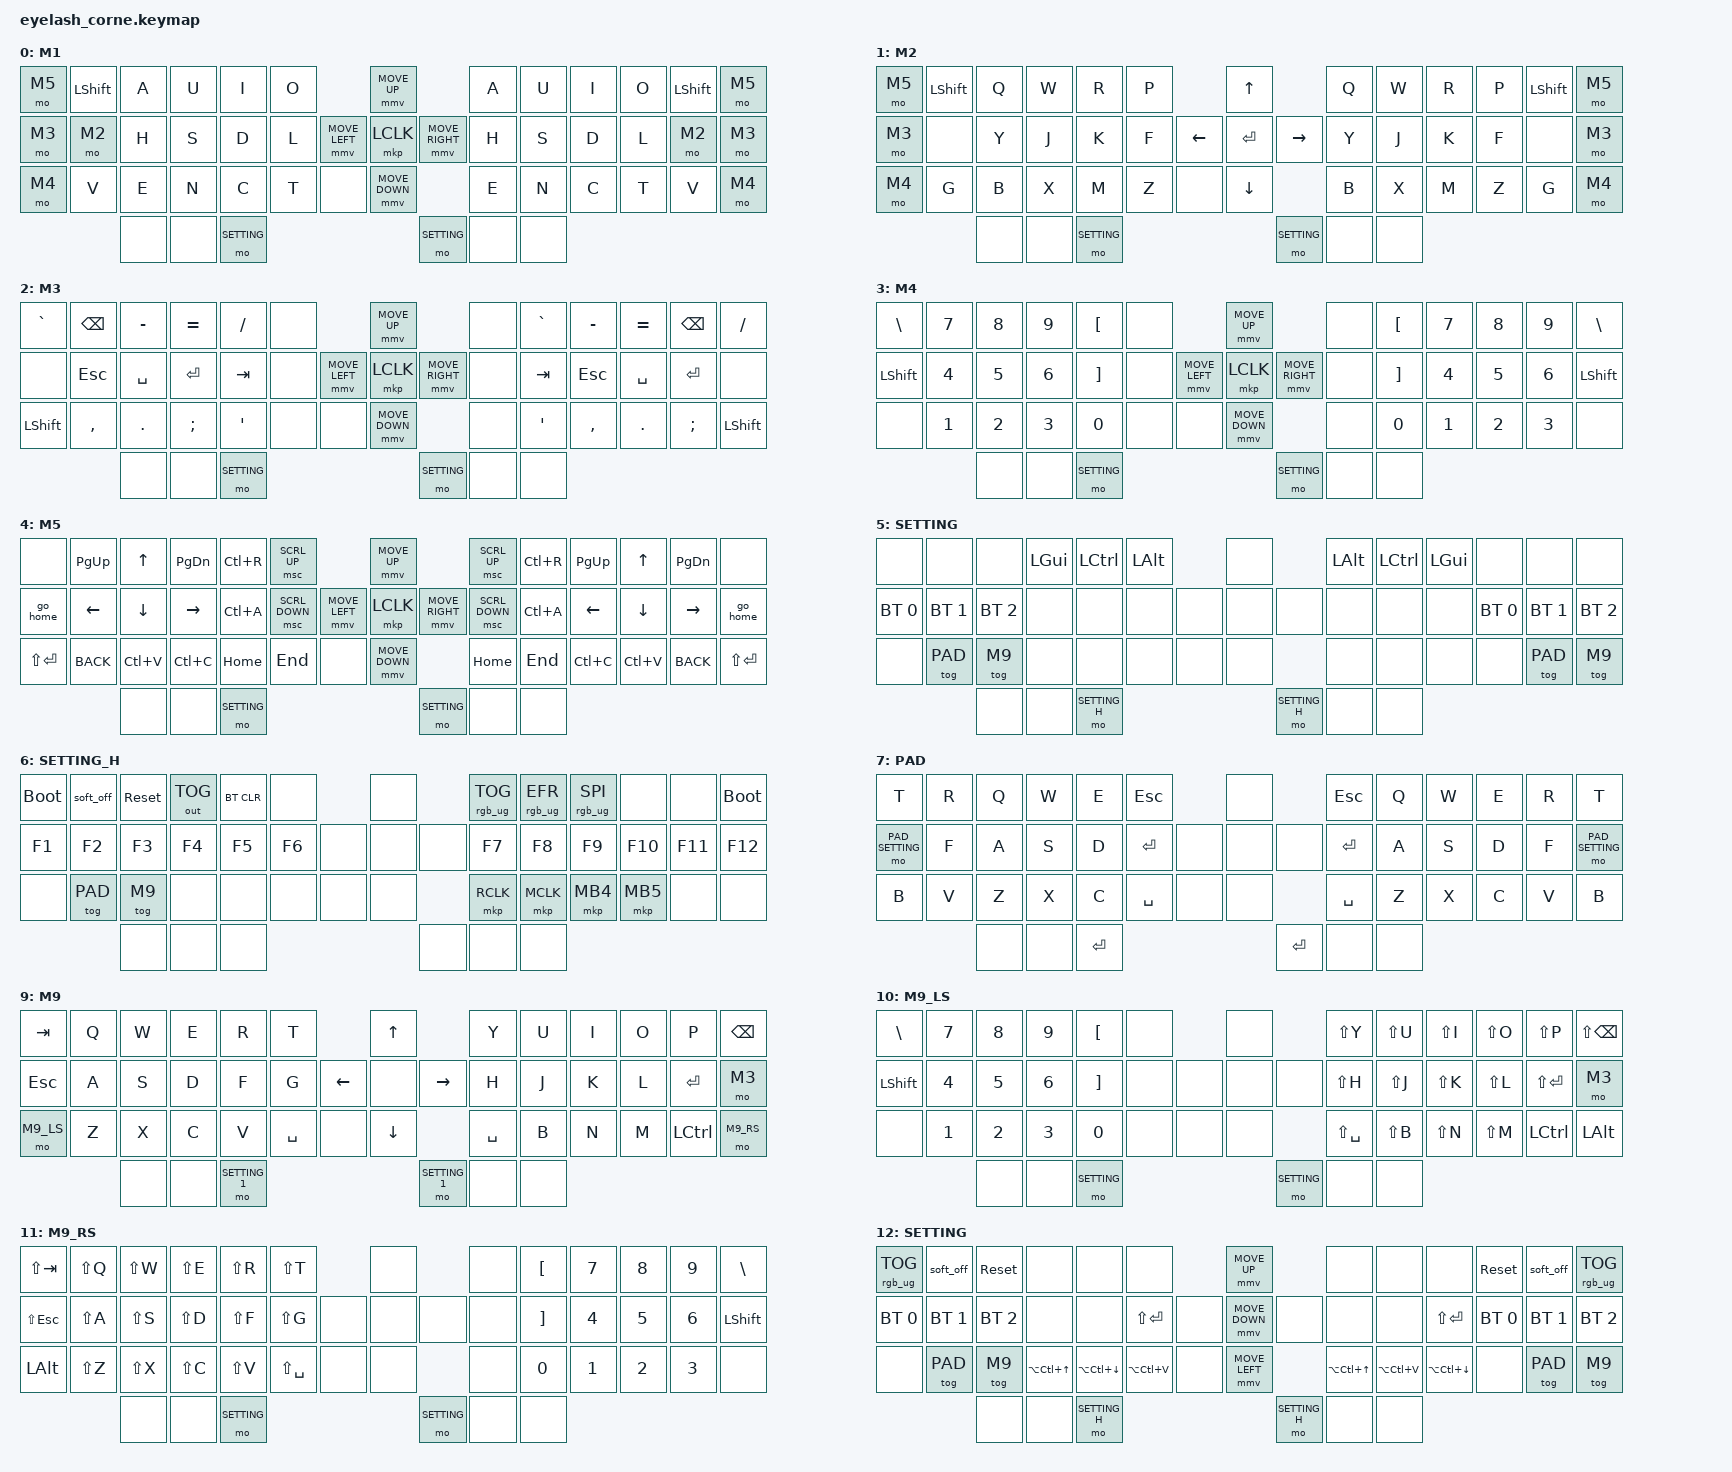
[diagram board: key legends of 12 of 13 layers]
#include <behaviors.dtsi>
#include <dt-bindings/zmk/bt.h>
#include <dt-bindings/zmk/keys.h>
#include <dt-bindings/zmk/mouse.h>
#include <dt-bindings/zmk/outputs.h>
#include <dt-bindings/zmk/rgb.h>

#include <input/processors.dtsi>


/*

   &mmv_input_listener {
       input-processors = <&zip_xy_scaler 2 1>;
   };

   &msc_input_listener {
       input-processors = <&zip_xy_scaler 2 1>;
   };

 */

#define ZMK_MOUSE_DEFAULT_MOVE_VAL 1200  // 600
#define ZMK_MOUSE_DEFAULT_SCRL_VAL 20    // 10
#define M1           0
#define M2           1
#define M3           2
#define M4           3
#define M5           4
#define SETTING      5
#define SETTING_H    6
#define PAD          7
#define PAD_SETTING  8
#define M9           9
#define M9_LS        10
#define M9_RS        11
#define SETTING_1    12

/ {
    macros {
        go_home: go_home {
            compatible = "zmk,behavior-macro";
            #binding-cells = <0>;
            bindings
                = <&macro_press &kp LGUI>
				, <&macro_wait_time 64>
                , <&macro_tap &kp ENTER>
                , <&macro_release &kp LGUI>
                ;
        };
    };

    rgb_encoder: rgb_encoder {
        compatible = "zmk,behavior-sensor-rotate";
        #sensor-binding-cells = <0>;
        bindings = <&rgb_ug RGB_BRI>, <&rgb_ug RGB_BRD>;
    };

    //scroll_encoder: scroll_encoder {
    //    compatible = "zmk,behavior-sensor-rotate";
    //    #sensor-binding-cells = <2>;
    //    bindings = <&msc SCRL_DOWN>, <&msc SCRL_UP>;
    //    tap-ms = <10>;
    //};
	rot_kp: sensor_rotate_kp {
		compatible = "zmk,behavior-sensor-rotate-var";
		#sensor-binding-cells = <2>;
		bindings = <&kp>, <&kp>;
		tap-ms = <10>;
	};

    keymap {
        compatible = "zmk,keymap";

        m1 {
            display-name = "M1";
		    bindings = <
&mo M5  &kp LEFT_SHIFT &kp A &kp U &kp I &kp O             	   &mmv MOVE_UP 			  &kp A &kp U &kp I &kp O &kp LEFT_SHIFT &mo M5
&mo M3  &mo M2         &kp H &kp S &kp D &kp L  &mmv MOVE_LEFT &mkp LCLK &mmv MOVE_RIGHT  &kp H &kp S &kp D &kp L &mo M2 		 &mo M3
&mo M4  &kp V          &kp E &kp N &kp C &kp T  &none          &mmv MOVE_DOWN             &kp E &kp N &kp C &kp T &kp V  		 &mo M4
					   &none  &none  &mo SETTING             		      	  &mo SETTING  &none  &none
            >;
			sensor-bindings = <&rot_kp PAGE_DOWN PAGE_UP>;
			//sensor-bindings = <&scroll_encoder>;
        };

        m2 {
            display-name = "M2";
            bindings = <
&mo M5 &kp LEFT_SHIFT &kp Q &kp W &kp R &kp P           &kp UP       		 &kp Q &kp W &kp R &kp P &kp LEFT_SHIFT &mo M5
&mo M3 &none          &kp Y &kp J &kp K &kp F  &kp LEFT &kp ENTER &kp RIGHT  &kp Y &kp J &kp K &kp F &none 		    &mo M3
&mo M4 &kp G          &kp B &kp X &kp M &kp Z  &none    &kp DOWN             &kp B &kp X &kp M &kp Z &kp G          &mo M4
					  &none  &none  &mo SETTING             						 	 &mo SETTING  &none  &none
            >;
			sensor-bindings = <&rot_kp PAGE_DOWN PAGE_UP>;
        };

        m3 {
            display-name = "M3";
            bindings = <
&kp GRAVE 	   &kp BSPC  &kp MINUS  &kp EQUAL &kp SLASH      &none 				   &mmv MOVE_UP 			  &none &kp GRAVE      &kp MINUS &kp EQUAL  &kp BSPC  &kp SLASH
&none     	   &kp ESC   &kp SPACE  &kp ENTER &kp TAB  	     &none  &mmv MOVE_LEFT &mkp LCLK &mmv MOVE_RIGHT  &none &kp TAB        &kp ESC   &kp SPACE  &kp ENTER &none
&kp LEFT_SHIFT &kp COMMA &kp PERIOD &kp SEMI  &kp APOSTROPHE &none  &none          &mmv MOVE_DOWN             &none &kp APOSTROPHE &kp COMMA &kp PERIOD &kp SEMI  &kp LEFT_SHIFT
								    &none  &none  &mo SETTING     			      					  		  &mo SETTING  &none  &none
            >;
			sensor-bindings = <&rot_kp PAGE_DOWN PAGE_UP>;
        };

        m4 {
            display-name = "M4";
            bindings = <
&kp BACKSLASH  &kp N7  &kp N8  &kp N9  &kp LEFT_BRACKET   &none 				&mmv MOVE_UP 	   	       &none  &kp LEFT_BRACKET   &kp N7  &kp N8  &kp N9  &kp BACKSLASH
&kp LEFT_SHIFT &kp N4  &kp N5  &kp N6  &kp RIGHT_BRACKET  &none  &mmv MOVE_LEFT &mkp LCLK &mmv MOVE_RIGHT  &none  &kp RIGHT_BRACKET  &kp N4  &kp N5  &kp N6  &kp LEFT_SHIFT
&none          &kp N1  &kp N2  &kp N3  &kp N0             &none  &none			&mmv MOVE_DOWN             &none  &kp N0             &kp N1  &kp N2  &kp N3  &none
							   &none  &none  &mo SETTING                      	   						   &mo SETTING  &none  &none
            >;
			sensor-bindings = <&rot_kp PAGE_DOWN PAGE_UP>;
        };

        m5 {
            display-name = "M5";
            bindings = <
&none         &kp PAGE_UP    &kp UP_ARROW   &kp PAGE_DOWN   &kp LC(R)  &msc SCRL_UP   				  &mmv MOVE_UP    		     &msc SCRL_UP        &kp LC(R)  &kp PAGE_UP     &kp UP_ARROW    &kp PAGE_DOWN    &none
&go_home      &kp LEFT_ARROW &kp DOWN_ARROW &kp RIGHT_ARROW &kp LC(A)  &msc SCRL_DOWN  &mmv MOVE_LEFT &mkp LCLK &mmv MOVE_RIGHT  &msc SCRL_DOWN        &kp LC(A)  &kp LEFT_ARROW  &kp DOWN_ARROW  &kp RIGHT_ARROW  &go_home
&kp LS(ENTER) &kp K_BACK     &kp LC(V)      &kp LC(C)		&kp HOME   &kp END         &none 		  &mmv MOVE_DOWN             &kp HOME   &kp END      &kp LC(C)       &kp LC(V)       &kp K_BACK       &kp LS(ENTER)
										  &none  &none  &mo SETTING                                                    		   &mo SETTING  &none  &none
            >;
			sensor-bindings = <&rot_kp PAGE_DOWN PAGE_UP>;
        };

        setting {
            display-name = "SETTING";
            bindings = <
&none 		 &none        &none   	   &kp LGUI &kp LCTRL &kp LALT        &none    	   &kp LALT &kp LCTRL &kp LGUI &none        &none        &none
&bt BT_SEL 0 &bt BT_SEL 1 &bt BT_SEL 2 &none    &none     &none     &none &none &none  &none    &none     &none &bt BT_SEL 0 &bt BT_SEL 1 &bt BT_SEL 2
&none        &tog PAD     &tog M9      &none    &none 	  &none     &none &none    	   &none    &none     &none &none        &tog PAD     &tog M9
										  &none &none  &mo SETTING_H 	   						     &mo SETTING_H &none  &none
            >;
            sensor-bindings = <&inc_dec_kp K_VOLUME_UP K_VOLUME_DOWN>;
        };

        setting_h {
            display-name = "SETTING_H";
            bindings = <
&bootloader &soft_off &sys_reset &out OUT_TOG &bt BT_CLR &none 		  &none        &rgb_ug RGB_TOG &rgb_ug RGB_EFR &rgb_ug RGB_SPI &none &none &bootloader
&kp F1 &kp F2 &kp F3 &kp F4 &kp F5 &kp F6 						&none &none &none  &kp F7 &kp F8 &kp F9 &kp F10 &kp F11 &kp F12
&none &tog PAD &tog M9 &none &none &none  						&none &none    	   &mkp RCLK &mkp MCLK &mkp MB4 &mkp MB5 &none &none
								&none &none  &none              &none &none &none
            >;
            sensor-bindings = <&rgb_encoder>;
        };

        pad {
            display-name = "PAD";
		    bindings = <
&kp T           &kp R &kp Q  &kp W &kp E &kp ESC   		  &none        &kp ESC   &kp Q &kp W  &kp E &kp R &kp T
&mo PAD_SETTING &kp F &kp A  &kp S &kp D &kp ENTER  &none &none &none  &kp ENTER &kp A &kp S  &kp D &kp F &mo PAD_SETTING
&kp B           &kp V &kp Z  &kp X &kp C &kp SPACE  &none &none    	   &kp SPACE &kp Z &kp X  &kp C &kp V &kp B
							   &none  &none  &kp ENTER                       &kp ENTER  &none  &none
            >;
			sensor-bindings = <&rot_kp PAGE_DOWN PAGE_UP>;
        };

        pad_setting {
            display-name = "PAD_SETTING";
		    bindings = <
&none &none &none  &none    &none  &none        &none        &none &none &none     &none &none &none
&none &none &none  &tog PAD &none  &none  &none &none &none  &none &none &tog PAD  &none &none &none
&none &none &none  &none    &none  &none  &none &none        &none &none &none     &none &none &none
					 &none  &none  &none                     	&none  &none  &none
&none
            >;
			sensor-bindings = <&rot_kp PAGE_DOWN PAGE_UP>;
        };

        m9 {
            display-name = "M9";
		    bindings = <
&kp TAB   &kp Q &kp W &kp E &kp R &kp T      			    &kp UP_ARROW       	   &kp Y     &kp U &kp I &kp O &kp P     &kp BSPC
&kp ESC   &kp A &kp S &kp D &kp F &kp G      &kp LEFT_ARROW &none &kp RIGHT_ARROW  &kp H     &kp J &kp K &kp L &kp ENTER &mo M3
&mo M9_LS &kp Z &kp X &kp C &kp V &kp SPACE  &none  		&kp DOWN_ARROW     	   &kp SPACE &kp B &kp N &kp M &kp LCTRL &mo M9_RS       
         			  &none  &none  &mo SETTING_1         						   &mo SETTING_1  &none  &none
            >;
			sensor-bindings = <&rot_kp PAGE_DOWN PAGE_UP>;
        };

        m9_ls {
            display-name = "M9_LS";
		    bindings = <
&kp BACKSLASH &kp N7 &kp N8 &kp N9 &kp LEFT_BRACKET  &none        	   &none        &kp LS(Y)     &kp LS(U) &kp LS(I) &kp LS(O) &kp LS(P)     &kp LS(BSPC)
&kp LSHIFT    &kp N4 &kp N5 &kp N6 &kp RIGHT_BRACKET &none       &none &none &none  &kp LS(H)     &kp LS(J) &kp LS(K) &kp LS(L) &kp LS(ENTER) &mo M3
&none         &kp N1 &kp N2 &kp N3 &kp N0            &none       &none &none        &kp LS(SPACE) &kp LS(B) &kp LS(N) &kp LS(M) &kp LCTRL     &kp LALT
          &none  &none  &mo SETTING   &mo SETTING  &none  &none
            >;
			sensor-bindings = <&rot_kp PAGE_DOWN PAGE_UP>;
        };

        m9_rs {
            display-name = "M9_RS";
		    bindings = <
&kp LS(TAB)  &kp LS(Q)  &kp LS(W)  &kp LS(E)  &kp LS(R)  &kp LS(T)        	  &none        &none  &kp LEFT_BRACKET   &kp N7 &kp N8 &kp N9 &kp BACKSLASH
&kp LS(ESC)  &kp LS(A)  &kp LS(S)  &kp LS(D)  &kp LS(F)  &kp LS(G)      &none &none &none  &none  &kp RIGHT_BRACKET  &kp N4 &kp N5 &kp N6 &kp LSHIFT
&kp LALT     &kp LS(Z)  &kp LS(X)  &kp LS(C)  &kp LS(V)  &kp LS(SPACE)  &none &none 	   &none  &kp N0             &kp N1 &kp N2 &kp N3 &none
         &none  &none  &mo SETTING   &mo SETTING  &none  &none
            >;
			sensor-bindings = <&rot_kp PAGE_DOWN PAGE_UP>;
        };

        setting_1 {
            display-name = "SETTING";
            bindings = <
&rgb_ug RGB_TOG  &soft_off     &sys_reset         &none                 &none                   &none            &mmv MOVE_UP      &none                 &none                   &none 	&sys_reset  &soft_off     &rgb_ug RGB_TOG
&bt BT_SEL 0     &bt BT_SEL 1  &bt BT_SEL 2  &none                 &none                   &kp LS(ENTER)    &none &mmv MOVE_DOWN &none    &none                 &none                   &kp LS(ENTER)    &bt BT_SEL 0     &bt BT_SEL 1  &bt BT_SEL 2
&none           &tog PAD         &tog M9         &kp LA(LC(UP_ARROW))  &kp LA(LC(DOWN_ARROW))  &kp LA(LC(V))   &none  &mmv MOVE_LEFT    &kp LA(LC(UP_ARROW)) &kp LA(LC(V)) &kp LA(LC(DOWN_ARROW))     &none           &tog PAD         &tog M9
                 &none &none  &mo SETTING_H    &mo SETTING_H &none  &none
            >;
            sensor-bindings = <&rgb_encoder>;
        };
    };
};
